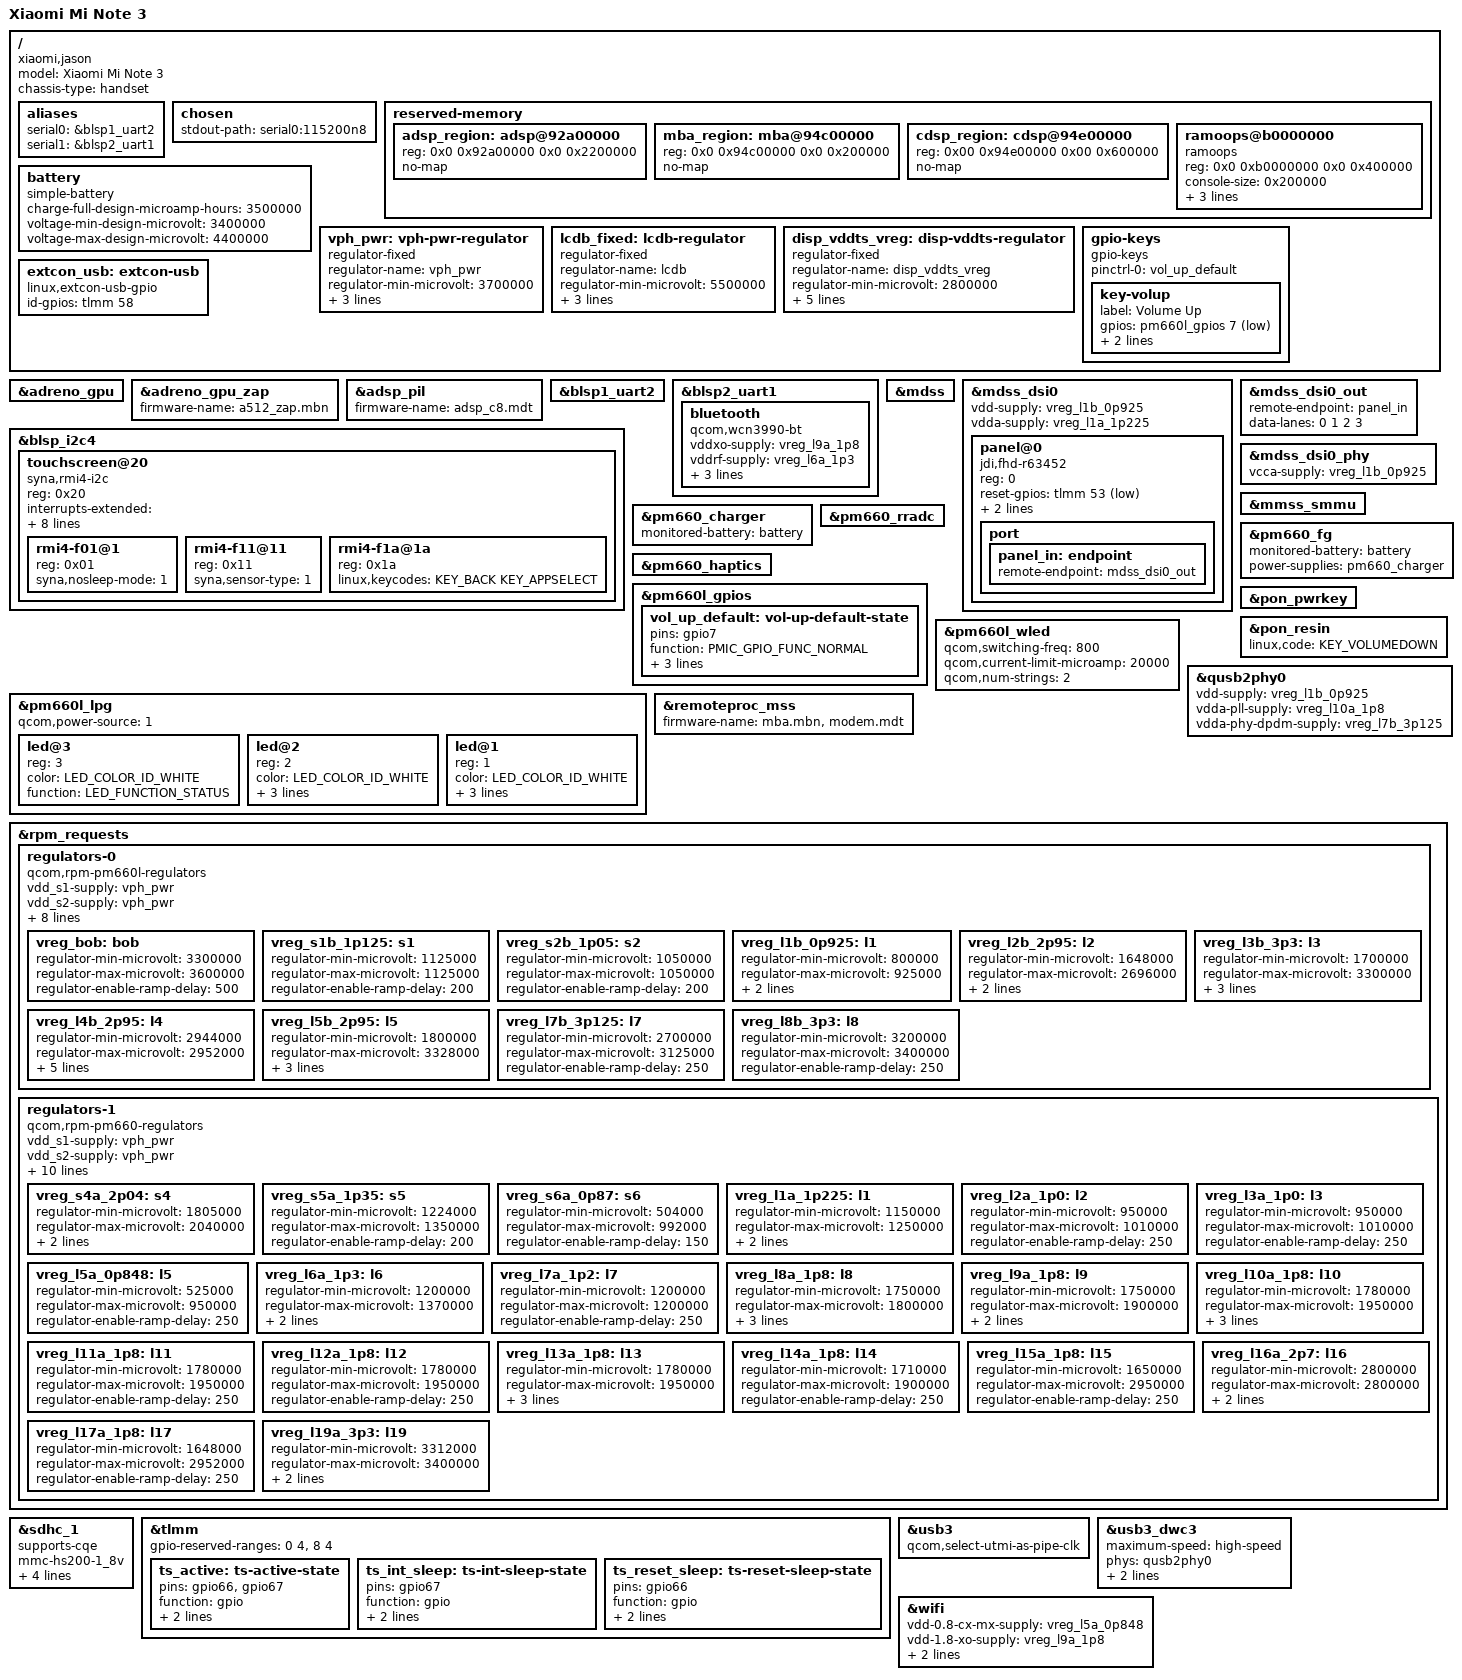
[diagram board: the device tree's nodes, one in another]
// SPDX-License-Identifier: (GPL-2.0+ OR BSD-3-Clause)
/*
 * Copyright (c) 2026, Xingyi Sun <Kernel114514@hotmail.com>
 * Copyright (c) 2026, Alexey Minnekhanov <alexeymin@minlexx.ru>
 */

/dts-v1/;

#include "sdm660.dtsi"
#include "pm660.dtsi"
#include "pm660l.dtsi"
#include <dt-bindings/input/input.h>
#include <dt-bindings/input/gpio-keys.h>
#include <dt-bindings/leds/common.h>
#include <dt-bindings/pinctrl/qcom,pmic-gpio.h>

/delete-node/ &adsp_region;
/delete-node/ &cdsp_region;
/delete-node/ &mba_region;

/ {
	model = "Xiaomi Mi Note 3";
	compatible = "xiaomi,jason", "qcom,sdm660";
	chassis-type = "handset";

	aliases {
		serial0 = &blsp1_uart2; /* Debug UART */
		serial1 = &blsp2_uart1; /* Bluetooth UART */
	};

	chosen {
		#address-cells = <2>;
		#size-cells = <2>;
		ranges;

		stdout-path = "serial0:115200n8";
	};

	reserved-memory {
		#address-cells = <2>;
		#size-cells = <2>;
		ranges;

		adsp_region: adsp@92a00000 {
			reg = <0x0 0x92a00000 0x0 0x2200000>;
			no-map;
		};

		mba_region: mba@94c00000 {
			reg = <0x0 0x94c00000 0x0 0x200000>;
			no-map;
		};

		cdsp_region: cdsp@94e00000 {
			reg = <0x00 0x94e00000 0x00 0x600000>;
			no-map;
		};

		ramoops@b0000000 {
			compatible = "ramoops";
			reg = <0x0 0xb0000000 0x0 0x400000>;
			console-size = <0x200000>;
			record-size = <0x0>;
			ftrace-size = <0x0>;
			pmsg-size = <0x200000>;
		};
	};

	battery: battery {
		compatible = "simple-battery";

		charge-full-design-microamp-hours = <3500000>;
		voltage-min-design-microvolt = <3400000>;
		voltage-max-design-microvolt = <4400000>;
	};

	vph_pwr: vph-pwr-regulator {
		compatible = "regulator-fixed";
		regulator-name = "vph_pwr";
		regulator-min-microvolt = <3700000>;
		regulator-max-microvolt = <3700000>;

		regulator-always-on;
		regulator-boot-on;
	};

	/*
	 * This is here until we have a driver for QPNP LCDB regulator.
	 * It can emulate both positive LDO and negative NCP supplies for panel.
	 */
	lcdb_fixed: lcdb-regulator {
		compatible = "regulator-fixed";
		regulator-name = "lcdb";
		/*
		 * Actual range for LCDB is 4.0 - 6.0V, but
		 * stock bootloader sets specific voltage 5.5V
		 */
		regulator-min-microvolt = <5500000>;
		regulator-max-microvolt = <5500000>;
		regulator-always-on;
		regulator-boot-on;
	};

	disp_vddts_vreg: disp-vddts-regulator {
		compatible = "regulator-fixed";
		regulator-name = "disp_vddts_vreg";
		regulator-min-microvolt = <2800000>;
		regulator-max-microvolt = <2800000>;
		startup-delay-us = <4000>;
		enable-active-high;
		regulator-boot-on;
		gpio = <&tlmm 73 GPIO_ACTIVE_HIGH>;
	};

	gpio-keys {
		compatible = "gpio-keys";

		pinctrl-0 = <&vol_up_default>;
		pinctrl-names = "default";

		key-volup {
			label = "Volume Up";
			gpios = <&pm660l_gpios 7 GPIO_ACTIVE_LOW>;
			linux,code = <KEY_VOLUMEUP>;
			debounce-interval = <15>;
		};
	};


	/*
	 * Until we hook up type-c detection, we
	 * have to stick with this. But it works.
	 */
	extcon_usb: extcon-usb {
		compatible = "linux,extcon-usb-gpio";
		id-gpios = <&tlmm 58 GPIO_ACTIVE_HIGH>;
	};
};

&adreno_gpu {
	status = "okay";
};

&adreno_gpu_zap {
	firmware-name = "a512_zap.mbn";
};

&adsp_pil {
	firmware-name = "adsp_c8.mdt";
};

&blsp1_uart2 {
	status = "okay";
};

&blsp2_uart1 {
	status = "okay";

	bluetooth {
		compatible = "qcom,wcn3990-bt";
		vddxo-supply = <&vreg_l9a_1p8>;
		vddrf-supply = <&vreg_l6a_1p3>;
		vddch0-supply = <&vreg_l19a_3p3>;
		vddio-supply = <&vreg_l13a_1p8>;
		max-speed = <3200000>;
	};
};

&blsp_i2c4 {
	status = "okay";

	/* Synaptics S3330 / S3331 / TD4322 */
	touchscreen@20 {
		compatible = "syna,rmi4-i2c";
		reg = <0x20>;

		#address-cells = <1>;
		#size-cells = <0>;
		interrupts-extended = <&tlmm 67 IRQ_TYPE_LEVEL_LOW>;

		pinctrl-0 = <&ts_active>;
		pinctrl-1 = <&ts_int_sleep &ts_reset_sleep>;
		pinctrl-names = "default", "sleep";

		vio-supply = <&vreg_l11a_1p8>;
		vdd-supply = <&disp_vddts_vreg>;

		reset-gpios = <&tlmm 66 GPIO_ACTIVE_LOW>;
		syna,reset-delay-ms = <200>;
		syna,startup-delay-ms = <600>;

		rmi4-f01@1 {
			reg = <0x01>;
			syna,nosleep-mode = <1>;
		};

		rmi4-f11@11 {
			reg = <0x11>;
			syna,sensor-type = <1>;
		};

		 rmi4-f1a@1a {
			reg = <0x1a>;
			/* Keys listed from right to left, rightmost key is KEY_BACK */
			linux,keycodes = <KEY_BACK KEY_APPSELECT>;
		};
	};
};

&mdss {
	status = "okay";
};

&mdss_dsi0 {
	#address-cells = <1>;
	#size-cells = <0>;

	vdd-supply = <&vreg_l1b_0p925>;
	vdda-supply = <&vreg_l1a_1p225>;

	status = "okay";

	panel@0 {
		compatible = "jdi,fhd-r63452";
		reg = <0>;
		reset-gpios = <&tlmm 53 GPIO_ACTIVE_LOW>;
		backlight = <&pm660l_wled>;

		power-supply = <&vreg_l11a_1p8>; /* vddio */
		/*
		 * Driver/bindings do not support extra supplies.
		 * when it does, add these:
		 * vddpos-supply = <&lcdb_fixed>;
		 * vddneg-supply = <&lcdb_fixed>;
		 */

		port {
			panel_in: endpoint {
				remote-endpoint = <&mdss_dsi0_out>;
			};
		};
	};
};

&mdss_dsi0_out {
	remote-endpoint = <&panel_in>;
	data-lanes = <0 1 2 3>;
};

&mdss_dsi0_phy {
	vcca-supply = <&vreg_l1b_0p925>;

	status = "okay";
};

&mmss_smmu {
	status = "okay";
};

&pm660_charger {
	monitored-battery = <&battery>;

	status = "okay";
};

&pm660_fg {
	monitored-battery = <&battery>;
	power-supplies = <&pm660_charger>;

	status = "okay";
};

&pm660_haptics {
	status = "okay";
};

&pm660_rradc {
	status = "okay";
};

&pm660l_gpios {
	vol_up_default: vol-up-default-state {
		pins = "gpio7";
		function = PMIC_GPIO_FUNC_NORMAL;
		bias-pull-up;
		input-enable;
		qcom,drive-strength = <PMIC_GPIO_STRENGTH_NO>;
	};
};

&pm660l_lpg {
	#address-cells = <1>;
	#size-cells = <0>;
	qcom,power-source = <1>;

	status = "okay";

	/* White notification LED */
	led@3 {
		reg = <3>; /* downstream uses pwm@b300, which is channel 3 */
		color = <LED_COLOR_ID_WHITE>;
		function = LED_FUNCTION_STATUS;
	};

	/* Back button backlight */
	led@2 {
		reg = <2>; /* downstream uses pwm@b200, which is channel 2 */
		color = <LED_COLOR_ID_WHITE>;
		function = LED_FUNCTION_KBD_BACKLIGHT;
		function-enumerator = <0>;
		default-state = "off";
	};

	/* AppSelect/Menu button backlight */
	led@1 {
		reg = <1>; /* downstream uses pwm@b100, which is channel 1 */
		color = <LED_COLOR_ID_WHITE>;
		function = LED_FUNCTION_KBD_BACKLIGHT;
		function-enumerator = <1>;
		default-state = "off";
	};
};

&pm660l_wled {
	qcom,switching-freq = <800>;
	qcom,current-limit-microamp = <20000>;
	qcom,num-strings = <2>;

	status = "okay";
};

&pon_pwrkey {
	status = "okay";
};

&pon_resin {
	linux,code = <KEY_VOLUMEDOWN>;

	status = "okay";
};

&qusb2phy0 {
	vdd-supply = <&vreg_l1b_0p925>;
	vdda-pll-supply = <&vreg_l10a_1p8>;
	vdda-phy-dpdm-supply = <&vreg_l7b_3p125>;

	status = "okay";
};

&remoteproc_mss {
	firmware-name = "mba.mbn", "modem.mdt";

	status = "okay";
};

&rpm_requests {
	regulators-0 {
		compatible = "qcom,rpm-pm660l-regulators";

		vdd_s1-supply = <&vph_pwr>;
		vdd_s2-supply = <&vph_pwr>;
		vdd_s3_s4-supply = <&vph_pwr>;
		vdd_s5-supply = <&vph_pwr>;
		vdd_s6-supply = <&vph_pwr>;

		vdd_l1_l9_l10-supply = <&vreg_s2b_1p05>;
		vdd_l2-supply = <&vreg_bob>;
		vdd_l3_l5_l7_l8-supply = <&vreg_bob>;
		vdd_l4_l6-supply = <&vreg_bob>;
		vdd_bob-supply = <&vph_pwr>;

		vreg_bob: bob {
			regulator-min-microvolt = <3300000>;
			regulator-max-microvolt = <3600000>;
			regulator-enable-ramp-delay = <500>;
		};

		vreg_s1b_1p125: s1 {
			regulator-min-microvolt = <1125000>;
			regulator-max-microvolt = <1125000>;
			regulator-enable-ramp-delay = <200>;
		};

		vreg_s2b_1p05: s2 {
			regulator-min-microvolt = <1050000>;
			regulator-max-microvolt = <1050000>;
			regulator-enable-ramp-delay = <200>;
		};

		/* LDOs */
		vreg_l1b_0p925: l1 {
			regulator-min-microvolt = <800000>;
			regulator-max-microvolt = <925000>;
			regulator-enable-ramp-delay = <250>;
			regulator-allow-set-load;
		};

		/* SDHCI 3.3V signal doesn't seem to be supported. */
		vreg_l2b_2p95: l2 {
			regulator-min-microvolt = <1648000>;
			regulator-max-microvolt = <2696000>;
			regulator-enable-ramp-delay = <250>;
			regulator-allow-set-load;
		};

		vreg_l3b_3p3: l3 {
			regulator-min-microvolt = <1700000>;
			regulator-max-microvolt = <3300000>;
			regulator-enable-ramp-delay = <250>;
			regulator-allow-set-load;
			regulator-always-on;
		};

		vreg_l4b_2p95: l4 {
			regulator-min-microvolt = <2944000>;
			regulator-max-microvolt = <2952000>;
			regulator-enable-ramp-delay = <250>;

			regulator-min-microamp = <200>;
			regulator-max-microamp = <600000>;
			regulator-system-load = <570000>;
			regulator-allow-set-load;
		};

		/*
		* Downstream specifies a range of 1721-3600mV,
		* but the only assigned consumers are SDHCI2 VMMC
		* and Coresight QPDI that both request pinned 2.95V.
		* Tighten the range to 1.8-3.328 (closest to 3.3) to
		* make the mmc driver happy.
		*/
		vreg_l5b_2p95: l5 {
			regulator-min-microvolt = <1800000>;
			regulator-max-microvolt = <3328000>;
			regulator-enable-ramp-delay = <250>;
			regulator-allow-set-load;
			regulator-system-load = <800000>;
		};

		vreg_l7b_3p125: l7 {
			regulator-min-microvolt = <2700000>;
			regulator-max-microvolt = <3125000>;
			regulator-enable-ramp-delay = <250>;
		};

		vreg_l8b_3p3: l8 {
			regulator-min-microvolt = <3200000>;
			regulator-max-microvolt = <3400000>;
			regulator-enable-ramp-delay = <250>;
		};
	};

	regulators-1 {
		compatible = "qcom,rpm-pm660-regulators";

		vdd_s1-supply = <&vph_pwr>;
		vdd_s2-supply = <&vph_pwr>;
		vdd_s3-supply = <&vph_pwr>;
		vdd_s4-supply = <&vph_pwr>;
		vdd_s5-supply = <&vph_pwr>;
		vdd_s6-supply = <&vph_pwr>;

		vdd_l1_l6_l7-supply = <&vreg_s5a_1p35>;
		vdd_l2_l3-supply = <&vreg_s2b_1p05>;
		vdd_l5-supply = <&vreg_s2b_1p05>;
		vdd_l8_l9_l10_l11_l12_l13_l14-supply = <&vreg_s4a_2p04>;
		vdd_l15_l16_l17_l18_l19-supply = <&vreg_bob>;

		/*
		* S1A (FTAPC0), S2A (FTAPC1), S3A (HFAPC1) are managed
		* by the Core Power Reduction hardened (CPRh) and the
		* Operating State Manager (OSM) HW automatically.
		*/

		vreg_s4a_2p04: s4 {
			regulator-min-microvolt = <1805000>;
			regulator-max-microvolt = <2040000>;
			regulator-enable-ramp-delay = <200>;
			regulator-always-on;
		};

		vreg_s5a_1p35: s5 {
			regulator-min-microvolt = <1224000>;
			regulator-max-microvolt = <1350000>;
			regulator-enable-ramp-delay = <200>;
		};

		vreg_s6a_0p87: s6 {
			regulator-min-microvolt = <504000>;
			regulator-max-microvolt = <992000>;
			regulator-enable-ramp-delay = <150>;
		};

		/* LDOs */
		vreg_l1a_1p225: l1 {
			regulator-min-microvolt = <1150000>;
			regulator-max-microvolt = <1250000>;
			regulator-enable-ramp-delay = <250>;
			regulator-allow-set-load;
		};

		vreg_l2a_1p0: l2 {
			regulator-min-microvolt = <950000>;
			regulator-max-microvolt = <1010000>;
			regulator-enable-ramp-delay = <250>;
		};

		vreg_l3a_1p0: l3 {
			regulator-min-microvolt = <950000>;
			regulator-max-microvolt = <1010000>;
			regulator-enable-ramp-delay = <250>;
		};

		vreg_l5a_0p848: l5 {
			regulator-min-microvolt = <525000>;
			regulator-max-microvolt = <950000>;
			regulator-enable-ramp-delay = <250>;
		};

		vreg_l6a_1p3: l6 {
			regulator-min-microvolt = <1200000>;
			regulator-max-microvolt = <1370000>;
			regulator-allow-set-load;
			regulator-enable-ramp-delay = <250>;
		};

		vreg_l7a_1p2: l7 {
			regulator-min-microvolt = <1200000>;
			regulator-max-microvolt = <1200000>;
			regulator-enable-ramp-delay = <250>;
		};

		vreg_l8a_1p8: l8 {
			regulator-min-microvolt = <1750000>;
			regulator-max-microvolt = <1800000>;
			regulator-enable-ramp-delay = <250>;
			regulator-system-load = <325000>;
			regulator-allow-set-load;
		};

		vreg_l9a_1p8: l9 {
			regulator-min-microvolt = <1750000>;
			regulator-max-microvolt = <1900000>;
			regulator-enable-ramp-delay = <250>;
			regulator-allow-set-load;
		};

		vreg_l10a_1p8: l10 {
			regulator-min-microvolt = <1780000>;
			regulator-max-microvolt = <1950000>;
			regulator-enable-ramp-delay = <250>;
			regulator-allow-set-load;
			regulator-system-load = <14000>;
		};

		vreg_l11a_1p8: l11 {
			regulator-min-microvolt = <1780000>;
			regulator-max-microvolt = <1950000>;
			regulator-enable-ramp-delay = <250>;
		};

		vreg_l12a_1p8: l12 {
			regulator-min-microvolt = <1780000>;
			regulator-max-microvolt = <1950000>;
			regulator-enable-ramp-delay = <250>;
		};

		vreg_l13a_1p8: l13 {
			regulator-min-microvolt = <1780000>;
			regulator-max-microvolt = <1950000>;
			regulator-enable-ramp-delay = <250>;
			regulator-boot-on;
			regulator-always-on;
		};

		vreg_l14a_1p8: l14 {
			regulator-min-microvolt = <1710000>;
			regulator-max-microvolt = <1900000>;
			regulator-enable-ramp-delay = <250>;
		};

		vreg_l15a_1p8: l15 {
			regulator-min-microvolt = <1650000>;
			regulator-max-microvolt = <2950000>;
			regulator-enable-ramp-delay = <250>;
		};

		vreg_l16a_2p7: l16 {
			regulator-min-microvolt = <2800000>;
			regulator-max-microvolt = <2800000>;
			regulator-enable-ramp-delay = <250>;
			regulator-always-on;
		};

		vreg_l17a_1p8: l17 {
			regulator-min-microvolt = <1648000>;
			regulator-max-microvolt = <2952000>;
			regulator-enable-ramp-delay = <250>;
		};

		vreg_l19a_3p3: l19 {
			regulator-min-microvolt = <3312000>;
			regulator-max-microvolt = <3400000>;
			regulator-enable-ramp-delay = <250>;
			regulator-allow-set-load;
		};
	};
};

&sdhc_1 {
	status = "okay";
	supports-cqe;

	mmc-hs200-1_8v;
	mmc-hs400-1_8v;
	mmc-hs400-enhanced-strobe;

	vmmc-supply = <&vreg_l4b_2p95>;
	vqmmc-supply = <&vreg_l8a_1p8>;
};

&tlmm {
	gpio-reserved-ranges = <0 4>, <8 4>;

	ts_active: ts-active-state {
		pins = "gpio66", "gpio67";
		function = "gpio";
		drive-strength = <16>;
		bias-pull-up;
	};

	ts_int_sleep: ts-int-sleep-state {
		pins = "gpio67";
		function = "gpio";
		drive-strength = <2>;
		bias-disable;
	};

	ts_reset_sleep: ts-reset-sleep-state {
		pins = "gpio66";
		function = "gpio";
		drive-strength = <2>;
		bias-pull-down;
	};
};

&usb3 {
	qcom,select-utmi-as-pipe-clk;

	status = "okay";
};

&usb3_dwc3 {
	maximum-speed = "high-speed";
	phys = <&qusb2phy0>;
	phy-names = "usb2-phy";

	dr_mode = "peripheral";
	extcon = <&extcon_usb>;
};

&wifi {
	vdd-0.8-cx-mx-supply = <&vreg_l5a_0p848>;
	vdd-1.8-xo-supply = <&vreg_l9a_1p8>;
	vdd-1.3-rfa-supply = <&vreg_l6a_1p3>;
	vdd-3.3-ch0-supply = <&vreg_l19a_3p3>;

	status = "okay";
};
